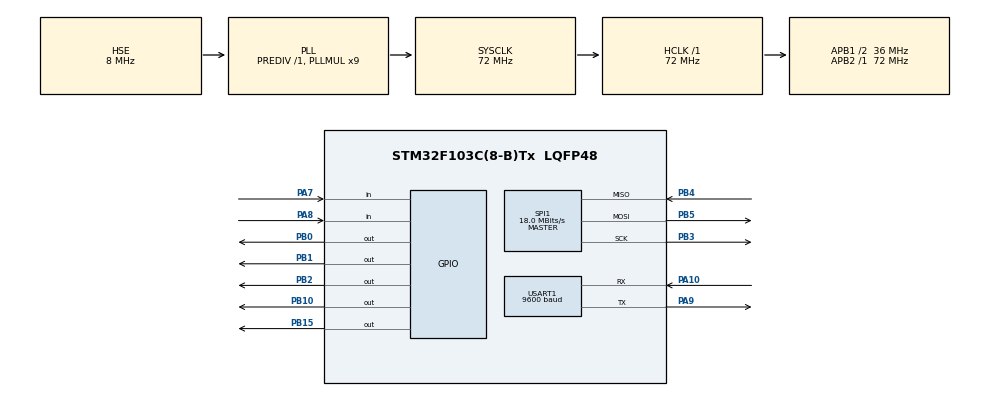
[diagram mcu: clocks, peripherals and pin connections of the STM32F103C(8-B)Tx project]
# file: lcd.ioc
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Mcu.Family=STM32F1
Mcu.Name=STM32F103C(8-B)Tx
Mcu.Package=LQFP48
NVIC.PriorityGroup=NVIC_PRIORITYGROUP_4
NVIC.USART1_IRQn=true\:0\:0\:false\:false\:true\:true\:true\:true
PA10.Mode=Asynchronous
PA10.Signal=USART1_RX
PA13.Mode=Serial_Wire
PA13.Signal=SYS_JTMS-SWDIO
PA14.Mode=Serial_Wire
PA14.Signal=SYS_JTCK-SWCLK
PA7.GPIO_PuPd=GPIO_PULLUP
PA7.Signal=GPIO_Input
PA8.GPIO_PuPd=GPIO_PULLUP
PA8.Signal=GPIO_Input
PA9.Mode=Asynchronous
PA9.Signal=USART1_TX
PB0.Signal=GPIO_Output
PB1.Signal=GPIO_Output
PB10.Signal=GPIO_Output
PB15.PinState=GPIO_PIN_RESET
PB15.Signal=GPIO_Output
PB2.Signal=GPIO_Output
PB3.Mode=Full_Duplex_Master
PB3.Signal=SPI1_SCK
PB4.Mode=Full_Duplex_Master
PB4.Signal=SPI1_MISO
PB5.Mode=Full_Duplex_Master
PB5.Signal=SPI1_MOSI
PD0-OSC_IN.Mode=HSE-External-Oscillator
PD0-OSC_IN.Signal=RCC_OSC_IN
PD1-OSC_OUT.Mode=HSE-External-Oscillator
PD1-OSC_OUT.Signal=RCC_OSC_OUT
ProjectManager.HeapSize=0x200
ProjectManager.StackSize=0x400
ProjectManager.TargetToolchain=MDK-ARM V5.27
RCC.AHBFreq_Value=72000000
RCC.APB1CLKDivider=RCC_HCLK_DIV2
RCC.APB1Freq_Value=36000000
RCC.APB1TimFreq_Value=72000000
RCC.APB2Freq_Value=72000000
RCC.APB2TimFreq_Value=72000000
RCC.HCLKFreq_Value=72000000
RCC.PLLMUL=RCC_PLL_MUL9
RCC.PLLSourceVirtual=RCC_PLLSOURCE_HSE
RCC.RTCClockSelection=RCC_RTCCLKSOURCE_HSE_DIV128
RCC.SYSCLKFreq_VALUE=72000000
RCC.SYSCLKSource=RCC_SYSCLKSOURCE_PLLCLK
RCC.USBFreq_Value=72000000
RTC.Date=15
RTC.Format=RTC_FORMAT_BIN
RTC.Hours=11
RTC.Minutes=47
RTC.WeekDay=RTC_WEEKDAY_SUNDAY
RTC.Year=23
SPI1.BaudRatePrescaler=SPI_BAUDRATEPRESCALER_4
SPI1.CLKPolarity=SPI_POLARITY_LOW
SPI1.CalculateBaudRate=18.0 MBits/s
SPI1.Direction=SPI_DIRECTION_2LINES
SPI1.Mode=SPI_MODE_MASTER
SPI1.VirtualType=VM_MASTER
TIM1.Channel-Output\ Compare1\ No\ Output=TIM_CHANNEL_1
USART1.BaudRate=9600
USART1.VirtualMode=VM_ASYNC
VP_RTC_VS_RTC_Activate.Mode=RTC_Enabled
VP_RTC_VS_RTC_Calendar.Mode=RTC_Calendar
VP_TIM1_VS_ClockSourceINT.Mode=Internal
VP_TIM1_VS_ClockSourceITR.Mode=TriggerSource_ITR1
VP_TIM1_VS_no_output1.Mode=Output Compare1 No Output
board=custom

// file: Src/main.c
/* USER CODE BEGIN Header */
/**
  ******************************************************************************
  * @file           : main.c
  * @brief          : Main program body
  ******************************************************************************
  * @attention
  *
  * <h2><center>&copy; Copyright (c) 2022 STMicroelectronics.
  * All rights reserved.</center></h2>
  *
  * This software component is licensed by ST under BSD 3-Clause license,
  * the "License"; You may not use this file except in compliance with the
  * License. You may obtain a copy of the License at:
  *                        opensource.org/licenses/BSD-3-Clause
  *
  ******************************************************************************
  */
/* USER CODE END Header */
#include "main.h"

/* USER CODE BEGIN Includes */
#include <stdio.h>
#include <string.h>
#include <stdlib.h>
#include <stdbool.h>

/* USER CODE END Includes */

/* USER CODE BEGIN PD */

#define CSX_PORT GPIOB
#define CSX_PIN GPIO_PIN_10

#define DC_PORT GPIOB
#define DC_PIN GPIO_PIN_0

#define RESET_PORT GPIOB
#define RESET_PIN GPIO_PIN_1

#define LCD_REST_LOW()   HAL_GPIO_WritePin(RESET_PORT, RESET_PIN, 0)
#define LCD_REST_HIGH()  HAL_GPIO_WritePin(RESET_PORT, RESET_PIN, 1)

#define LCD_DC_LOW()     HAL_GPIO_WritePin(DC_PORT, DC_PIN, 0)
#define LCD_DC_HIGH()    HAL_GPIO_WritePin(DC_PORT, DC_PIN, 1)

#define LCD_CS_LOW()     HAL_GPIO_WritePin(CSX_PORT, CSX_PIN, 0)
#define LCD_CS_HIGH()    HAL_GPIO_WritePin(CSX_PORT, CSX_PIN, 1)

const unsigned char ascii_3216[][64]={
{0x00,0x00,0x00,0x00,0x00,0x00,0x00,0x00,0x00,0x00,0x00,0x00,0x00,0x00,0x00,0x00,0x00,0x00,0x00,0x00,0x00,0x00,0x00,0x00,0x00,0x00,0x00,0x00,0x00,0x00,0x00,0x00,0x00,0x00,0x00,0x00,0x00,0x00,0x00,0x00,0x00,0x00,0x00,0x00,0x00,0x00,0x00,0x00,0x00,0x00,0x00,0x00,0x00,0x00,0x00,0x00,0x00,0x00,0x00,0x00,0x00,0x00,0x00,0x00},/*" ",0*/
{0x00,0x00,0x00,0x00,0x00,0x00,0x00,0x00,0x00,0x00,0xC0,0x01,0xC0,0x01,0xC0,0x01,0xC0,0x01,0xC0,0x01,0xC0,0x01,0xC0,0x01,0x80,0x00,0x80,0x00,0x80,0x00,0x80,0x00,0x80,0x00,0x80,0x00,0x80,0x00,0x00,0x00,0x00,0x00,0x00,0x00,0x00,0x00,0x80,0x01,0xC0,0x03,0xC0,0x03,0x80,0x01,0x00,0x00,0x00,0x00,0x00,0x00,0x00,0x00,0x00,0x00},/*"!",1*/
{0x00,0x00,0x00,0x00,0x00,0x00,0xE0,0x1C,0xE0,0x1C,0xF0,0x1E,0x70,0x0E,0x38,0x07,0x18,0x03,0x08,0x01,0x84,0x00,0x00,0x00,0x00,0x00,0x00,0x00,0x00,0x00,0x00,0x00,0x00,0x00,0x00,0x00,0x00,0x00,0x00,0x00,0x00,0x00,0x00,0x00,0x00,0x00,0x00,0x00,0x00,0x00,0x00,0x00,0x00,0x00,0x00,0x00,0x00,0x00,0x00,0x00,0x00,0x00,0x00,0x00},/*""",2*/
{0x00,0x00,0x00,0x00,0x00,0x00,0x00,0x00,0x00,0x00,0x00,0x00,0x20,0x10,0x20,0x10,0x20,0x10,0x20,0x10,0x20,0x10,0xFE,0x7F,0xFE,0x7F,0x10,0x08,0x10,0x08,0x10,0x08,0x10,0x08,0x10,0x08,0x10,0x08,0x10,0x08,0xFE,0x7F,0xFE,0x7F,0x08,0x04,0x08,0x04,0x08,0x04,0x08,0x04,0x08,0x04,0x00,0x00,0x00,0x00,0x00,0x00,0x00,0x00,0x00,0x00},/*"#",3*/
{0x00,0x00,0x00,0x00,0x00,0x00,0x00,0x00,0x00,0x01,0x00,0x01,0xC0,0x07,0x60,0x19,0x10,0x31,0x18,0x31,0x18,0x39,0x18,0x39,0x38,0x01,0x70,0x01,0xE0,0x01,0xC0,0x03,0x80,0x07,0x00,0x0F,0x00,0x1D,0x00,0x39,0x00,0x31,0x1C,0x31,0x1C,0x31,0x0C,0x31,0x0C,0x11,0x18,0x0D,0xE0,0x07,0x00,0x01,0x00,0x01,0x00,0x01,0x00,0x00,0x00,0x00},/*"$",4*/
{0x00,0x00,0x00,0x00,0x00,0x00,0x00,0x00,0x00,0x00,0x00,0x00,0x1C,0x10,0x36,0x18,0x63,0x08,0x63,0x0C,0x63,0x04,0x63,0x04,0x63,0x02,0x63,0x02,0x63,0x01,0x36,0x1D,0x9C,0x37,0x80,0x22,0x80,0x63,0x40,0x63,0x40,0x63,0x20,0x63,0x20,0x63,0x30,0x63,0x10,0x22,0x18,0x36,0x08,0x1C,0x00,0x00,0x00,0x00,0x00,0x00,0x00,0x00,0x00,0x00},/*"%",5*/
{0x00,0x00,0x00,0x00,0x00,0x00,0x00,0x00,0x00,0x00,0x00,0x00,0xF0,0x00,0x98,0x01,0x8C,0x01,0x8C,0x01,0x8C,0x01,0x8C,0x01,0x8C,0x00,0xCC,0x00,0x78,0x00,0x18,0x3E,0x1C,0x08,0x36,0x08,0x32,0x08,0x63,0x04,0x63,0x04,0xC3,0x04,0xC3,0x03,0x83,0x43,0x06,0x43,0x8E,0x26,0x78,0x1C,0x00,0x00,0x00,0x00,0x00,0x00,0x00,0x00,0x00,0x00},/*"&",6*/
{0x00,0x00,0x00,0x00,0x00,0x00,0x1C,0x00,0x3C,0x00,0x3C,0x00,0x30,0x00,0x30,0x00,0x10,0x00,0x0C,0x00,0x06,0x00,0x00,0x00,0x00,0x00,0x00,0x00,0x00,0x00,0x00,0x00,0x00,0x00,0x00,0x00,0x00,0x00,0x00,0x00,0x00,0x00,0x00,0x00,0x00,0x00,0x00,0x00,0x00,0x00,0x00,0x00,0x00,0x00,0x00,0x00,0x00,0x00,0x00,0x00,0x00,0x00,0x00,0x00},/*"'",7*/
{0x00,0x00,0x00,0x00,0x00,0x00,0x00,0x40,0x00,0x20,0x00,0x10,0x00,0x08,0x00,0x0C,0x00,0x04,0x00,0x06,0x00,0x03,0x00,0x03,0x00,0x03,0x80,0x01,0x80,0x01,0x80,0x01,0x80,0x01,0x80,0x01,0x80,0x01,0x80,0x01,0x80,0x01,0x00,0x03,0x00,0x03,0x00,0x03,0x00,0x06,0x00,0x06,0x00,0x0C,0x00,0x08,0x00,0x10,0x00,0x20,0x00,0x40,0x00,0x00},/*"(",8*/
{0x00,0x00,0x00,0x00,0x00,0x00,0x02,0x00,0x04,0x00,0x08,0x00,0x10,0x00,0x30,0x00,0x20,0x00,0x60,0x00,0xC0,0x00,0xC0,0x00,0xC0,0x00,0x80,0x01,0x80,0x01,0x80,0x01,0x80,0x01,0x80,0x01,0x80,0x01,0x80,0x01,0x80,0x01,0xC0,0x00,0xC0,0x00,0xC0,0x00,0x60,0x00,0x60,0x00,0x30,0x00,0x10,0x00,0x08,0x00,0x04,0x00,0x02,0x00,0x00,0x00},/*")",9*/
{0x00,0x00,0x00,0x00,0x00,0x00,0x00,0x00,0x00,0x00,0x00,0x00,0x00,0x00,0x00,0x00,0x00,0x01,0x80,0x03,0x80,0x03,0x00,0x01,0x1C,0x71,0x3C,0x79,0x78,0x3D,0xC0,0x07,0x00,0x01,0xC0,0x07,0x78,0x3D,0x3C,0x79,0x1C,0x71,0x00,0x01,0x80,0x03,0x80,0x03,0x80,0x01,0x00,0x00,0x00,0x00,0x00,0x00,0x00,0x00,0x00,0x00,0x00,0x00,0x00,0x00},/*"*",10*/
{0x00,0x00,0x00,0x00,0x00,0x00,0x00,0x00,0x00,0x00,0x00,0x00,0x00,0x00,0x00,0x00,0x00,0x00,0x00,0x01,0x00,0x01,0x00,0x01,0x00,0x01,0x00,0x01,0x00,0x01,0x00,0x01,0xFC,0x7F,0x00,0x01,0x00,0x01,0x00,0x01,0x00,0x01,0x00,0x01,0x00,0x01,0x00,0x01,0x00,0x00,0x00,0x00,0x00,0x00,0x00,0x00,0x00,0x00,0x00,0x00,0x00,0x00,0x00,0x00},/*"+",11*/
{0x00,0x00,0x00,0x00,0x00,0x00,0x00,0x00,0x00,0x00,0x00,0x00,0x00,0x00,0x00,0x00,0x00,0x00,0x00,0x00,0x00,0x00,0x00,0x00,0x00,0x00,0x00,0x00,0x00,0x00,0x00,0x00,0x00,0x00,0x00,0x00,0x00,0x00,0x00,0x00,0x00,0x00,0x00,0x00,0x00,0x00,0x00,0x00,0x1C,0x00,0x3C,0x00,0x3C,0x00,0x30,0x00,0x30,0x00,0x10,0x00,0x0C,0x00,0x06,0x00},/*",",12*/
{0x00,0x00,0x00,0x00,0x00,0x00,0x00,0x00,0x00,0x00,0x00,0x00,0x00,0x00,0x00,0x00,0x00,0x00,0x00,0x00,0x00,0x00,0x00,0x00,0x00,0x00,0x00,0x00,0x00,0x00,0x00,0x00,0xFE,0x7F,0x00,0x00,0x00,0x00,0x00,0x00,0x00,0x00,0x00,0x00,0x00,0x00,0x00,0x00,0x00,0x00,0x00,0x00,0x00,0x00,0x00,0x00,0x00,0x00,0x00,0x00,0x00,0x00,0x00,0x00},/*"-",13*/
{0x00,0x00,0x00,0x00,0x00,0x00,0x00,0x00,0x00,0x00,0x00,0x00,0x00,0x00,0x00,0x00,0x00,0x00,0x00,0x00,0x00,0x00,0x00,0x00,0x00,0x00,0x00,0x00,0x00,0x00,0x00,0x00,0x00,0x00,0x00,0x00,0x00,0x00,0x00,0x00,0x00,0x00,0x00,0x00,0x00,0x00,0x18,0x00,0x3C,0x00,0x3C,0x00,0x18,0x00,0x00,0x00,0x00,0x00,0x00,0x00,0x00,0x00,0x00,0x00},/*".",14*/
{0x00,0x00,0x00,0x00,0x00,0x00,0x00,0x40,0x00,0x60,0x00,0x20,0x00,0x30,0x00,0x10,0x00,0x18,0x00,0x08,0x00,0x0C,0x00,0x04,0x00,0x06,0x00,0x02,0x00,0x03,0x00,0x01,0x80,0x01,0x80,0x00,0xC0,0x00,0x40,0x00,0x60,0x00,0x20,0x00,0x30,0x00,0x10,0x00,0x18,0x00,0x08,0x00,0x0C,0x00,0x04,0x00,0x06,0x00,0x02,0x00,0x00,0x00,0x00,0x00},/*"/",15*/
{0x00,0x00,0x00,0x00,0x00,0x00,0x00,0x00,0x00,0x00,0x00,0x00,0xC0,0x07,0x60,0x0C,0x30,0x18,0x18,0x30,0x18,0x30,0x18,0x20,0x0C,0x60,0x0C,0x60,0x0C,0x60,0x0C,0x60,0x0C,0x60,0x0C,0x60,0x0C,0x60,0x0C,0x60,0x0C,0x60,0x18,0x20,0x18,0x30,0x18,0x30,0x30,0x18,0x60,0x0C,0xC0,0x07,0x00,0x00,0x00,0x00,0x00,0x00,0x00,0x00,0x00,0x00},/*"0",16*/
{0x00,0x00,0x00,0x00,0x00,0x00,0x00,0x00,0x00,0x00,0x00,0x00,0x00,0x01,0x80,0x01,0xF8,0x01,0x80,0x01,0x80,0x01,0x80,0x01,0x80,0x01,0x80,0x01,0x80,0x01,0x80,0x01,0x80,0x01,0x80,0x01,0x80,0x01,0x80,0x01,0x80,0x01,0x80,0x01,0x80,0x01,0x80,0x01,0x80,0x01,0xC0,0x03,0xF8,0x1F,0x00,0x00,0x00,0x00,0x00,0x00,0x00,0x00,0x00,0x00},/*"1",17*/
{0x00,0x00,0x00,0x00,0x00,0x00,0x00,0x00,0x00,0x00,0x00,0x00,0xE0,0x07,0x10,0x1C,0x08,0x18,0x04,0x30,0x04,0x30,0x0C,0x30,0x0C,0x30,0x00,0x30,0x00,0x18,0x00,0x08,0x00,0x04,0x00,0x02,0x00,0x01,0x80,0x00,0x40,0x00,0x20,0x20,0x10,0x20,0x08,0x20,0x04,0x30,0xFC,0x1F,0xFC,0x1F,0x00,0x00,0x00,0x00,0x00,0x00,0x00,0x00,0x00,0x00},/*"2",18*/
{0x00,0x00,0x00,0x00,0x00,0x00,0x00,0x00,0x00,0x00,0x00,0x00,0xE0,0x03,0x18,0x0E,0x0C,0x0C,0x0C,0x18,0x0C,0x18,0x0C,0x18,0x00,0x18,0x00,0x0C,0x00,0x06,0xC0,0x03,0x00,0x0E,0x00,0x18,0x00,0x10,0x00,0x30,0x00,0x30,0x0C,0x30,0x0C,0x30,0x0C,0x10,0x0C,0x18,0x18,0x0C,0xE0,0x03,0x00,0x00,0x00,0x00,0x00,0x00,0x00,0x00,0x00,0x00},/*"3",19*/
{0x00,0x00,0x00,0x00,0x00,0x00,0x00,0x00,0x00,0x00,0x00,0x00,0x00,0x0C,0x00,0x0E,0x00,0x0E,0x00,0x0F,0x80,0x0E,0x80,0x0E,0x40,0x0E,0x60,0x0E,0x20,0x0E,0x10,0x0E,0x10,0x0E,0x08,0x0E,0x04,0x0E,0x04,0x0E,0xFE,0x7F,0x00,0x0E,0x00,0x0E,0x00,0x0E,0x00,0x0E,0x00,0x0E,0x00,0x0E,0xC0,0x7F,0x00,0x00,0x00,0x00,0x00,0x00,0x00,0x00},/*"4",20*/
{0x00,0x00,0x00,0x00,0x00,0x00,0x00,0x00,0x00,0x00,0x00,0x00,0xF0,0x3F,0xF0,0x3F,0x10,0x00,0x10,0x00,0x10,0x00,0x08,0x00,0x08,0x00,0xC8,0x07,0x28,0x0C,0x18,0x18,0x08,0x10,0x00,0x30,0x00,0x30,0x00,0x30,0x00,0x30,0x0C,0x30,0x0C,0x30,0x04,0x18,0x04,0x18,0x08,0x0C,0xF0,0x03,0x00,0x00,0x00,0x00,0x00,0x00,0x00,0x00,0x00,0x00},/*"5",21*/
{0x00,0x00,0x00,0x00,0x00,0x00,0x00,0x00,0x00,0x00,0x00,0x00,0x80,0x0F,0xC0,0x10,0x20,0x30,0x10,0x30,0x18,0x00,0x18,0x00,0x08,0x00,0x0C,0x00,0x8C,0x0F,0x6C,0x18,0x3C,0x30,0x1C,0x60,0x0C,0x60,0x0C,0x60,0x0C,0x60,0x0C,0x60,0x18,0x60,0x18,0x20,0x30,0x30,0x60,0x18,0xC0,0x07,0x00,0x00,0x00,0x00,0x00,0x00,0x00,0x00,0x00,0x00},/*"6",22*/
{0x00,0x00,0x00,0x00,0x00,0x00,0x00,0x00,0x00,0x00,0x00,0x00,0xF8,0x3F,0xF8,0x3F,0x1C,0x10,0x0C,0x08,0x04,0x08,0x04,0x04,0x00,0x04,0x00,0x02,0x00,0x02,0x00,0x01,0x00,0x01,0x00,0x01,0x80,0x00,0x80,0x00,0x80,0x00,0xC0,0x00,0xC0,0x00,0xC0,0x00,0xC0,0x00,0xC0,0x00,0xC0,0x00,0x00,0x00,0x00,0x00,0x00,0x00,0x00,0x00,0x00,0x00},/*"7",23*/
{0x00,0x00,0x00,0x00,0x00,0x00,0x00,0x00,0x00,0x00,0x00,0x00,0xE0,0x07,0x30,0x0C,0x18,0x18,0x0C,0x30,0x0C,0x30,0x0C,0x30,0x1C,0x30,0x38,0x18,0x70,0x08,0xE0,0x07,0xB0,0x07,0x18,0x0E,0x0C,0x1C,0x06,0x38,0x06,0x30,0x06,0x30,0x06,0x30,0x06,0x30,0x0C,0x18,0x18,0x0C,0xE0,0x03,0x00,0x00,0x00,0x00,0x00,0x00,0x00,0x00,0x00,0x00},/*"8",24*/
{0x00,0x00,0x00,0x00,0x00,0x00,0x00,0x00,0x00,0x00,0x00,0x00,0xE0,0x03,0x18,0x04,0x0C,0x08,0x0C,0x18,0x06,0x10,0x06,0x30,0x06,0x30,0x06,0x30,0x06,0x30,0x06,0x38,0x0C,0x3C,0x18,0x36,0xF0,0x31,0x00,0x30,0x00,0x18,0x00,0x18,0x00,0x18,0x0C,0x0C,0x0C,0x06,0x0C,0x03,0xF0,0x01,0x00,0x00,0x00,0x00,0x00,0x00,0x00,0x00,0x00,0x00},/*"9",25*/
{0x00,0x00,0x00,0x00,0x00,0x00,0x00,0x00,0x00,0x00,0x00,0x00,0x00,0x00,0x00,0x00,0x00,0x00,0x00,0x00,0x00,0x00,0x00,0x00,0x00,0x00,0x80,0x01,0xC0,0x03,0xC0,0x03,0x80,0x01,0x00,0x00,0x00,0x00,0x00,0x00,0x00,0x00,0x00,0x00,0x00,0x00,0x80,0x01,0xC0,0x03,0xC0,0x03,0x80,0x01,0x00,0x00,0x00,0x00,0x00,0x00,0x00,0x00,0x00,0x00},/*":",26*/
{0x00,0x00,0x00,0x00,0x00,0x00,0x00,0x00,0x00,0x00,0x00,0x00,0x00,0x00,0x00,0x00,0x00,0x00,0x00,0x00,0x00,0x00,0x00,0x00,0x00,0x00,0xC0,0x00,0xC0,0x00,0x00,0x00,0x00,0x00,0x00,0x00,0x00,0x00,0x00,0x00,0x00,0x00,0x00,0x00,0x00,0x00,0x00,0x00,0x00,0x00,0xC0,0x00,0xC0,0x00,0x80,0x00,0x80,0x00,0x40,0x00,0x40,0x00,0x00,0x00},/*";",27*/
{0x00,0x00,0x00,0x00,0x00,0x00,0x00,0x00,0x00,0x00,0x00,0x20,0x00,0x10,0x00,0x08,0x00,0x04,0x00,0x06,0x00,0x03,0x80,0x01,0xC0,0x00,0x60,0x00,0x30,0x00,0x18,0x00,0x0C,0x00,0x18,0x00,0x30,0x00,0x60,0x00,0xC0,0x00,0x80,0x01,0x00,0x03,0x00,0x06,0x00,0x04,0x00,0x08,0x00,0x10,0x00,0x20,0x00,0x00,0x00,0x00,0x00,0x00,0x00,0x00},/*"<",28*/
{0x00,0x00,0x00,0x00,0x00,0x00,0x00,0x00,0x00,0x00,0x00,0x00,0x00,0x00,0x00,0x00,0x00,0x00,0x00,0x00,0x00,0x00,0x00,0x00,0x00,0x00,0xFE,0x7F,0x00,0x00,0x00,0x00,0x00,0x00,0x00,0x00,0x00,0x00,0xFE,0x7F,0x00,0x00,0x00,0x00,0x00,0x00,0x00,0x00,0x00,0x00,0x00,0x00,0x00,0x00,0x00,0x00,0x00,0x00,0x00,0x00,0x00,0x00,0x00,0x00},/*"=",29*/
{0x00,0x00,0x00,0x00,0x00,0x00,0x00,0x00,0x00,0x00,0x04,0x00,0x08,0x00,0x10,0x00,0x20,0x00,0x60,0x00,0xC0,0x00,0x80,0x01,0x00,0x03,0x00,0x06,0x00,0x0C,0x00,0x18,0x00,0x30,0x00,0x18,0x00,0x0C,0x00,0x06,0x00,0x03,0x80,0x01,0xC0,0x00,0x60,0x00,0x20,0x00,0x10,0x00,0x08,0x00,0x04,0x00,0x00,0x00,0x00,0x00,0x00,0x00,0x00,0x00},/*">",30*/
{0x00,0x00,0x00,0x00,0x00,0x00,0x00,0x00,0x00,0x00,0xC0,0x07,0x30,0x18,0x08,0x30,0x08,0x60,0x0C,0x60,0x1C,0x60,0x1C,0x60,0x1C,0x60,0x00,0x30,0x00,0x1C,0x00,0x06,0x00,0x01,0x80,0x00,0x80,0x00,0x80,0x00,0x80,0x00,0x00,0x00,0x00,0x00,0x80,0x01,0xC0,0x03,0xC0,0x03,0x80,0x01,0x00,0x00,0x00,0x00,0x00,0x00,0x00,0x00,0x00,0x00},/*"?",31*/
{0x00,0x00,0x00,0x00,0x00,0x00,0x00,0x00,0x00,0x00,0x00,0x00,0xC0,0x07,0x60,0x18,0x10,0x30,0x18,0x20,0x0C,0x2F,0x8C,0x4D,0x86,0x4C,0xC6,0x4C,0xC6,0x4C,0x66,0x4C,0x66,0x44,0x66,0x44,0x66,0x26,0x66,0x26,0x66,0x15,0xCC,0x1C,0x0C,0x40,0x08,0x20,0x18,0x30,0x30,0x18,0xC0,0x07,0x00,0x00,0x00,0x00,0x00,0x00,0x00,0x00,0x00,0x00},/*"@",32*/
{0x00,0x00,0x00,0x00,0x00,0x00,0x00,0x00,0x00,0x00,0x00,0x01,0xC0,0x01,0xC0,0x01,0xC0,0x01,0x40,0x01,0x60,0x03,0x20,0x03,0x20,0x03,0x20,0x03,0x30,0x06,0x10,0x06,0x10,0x06,0x10,0x06,0xF8,0x0F,0x08,0x0C,0x08,0x0C,0x08,0x0C,0x0C,0x0C,0x04,0x18,0x04,0x18,0x06,0x18,0x1F,0x7C,0x00,0x00,0x00,0x00,0x00,0x00,0x00,0x00,0x00,0x00},/*"A",33*/
{0x00,0x00,0x00,0x00,0x00,0x00,0x00,0x00,0x00,0x00,0x00,0x00,0xFE,0x07,0x18,0x1C,0x18,0x38,0x18,0x30,0x18,0x30,0x18,0x30,0x18,0x30,0x18,0x18,0x18,0x0C,0xF8,0x07,0x18,0x18,0x18,0x30,0x18,0x20,0x18,0x60,0x18,0x60,0x18,0x60,0x18,0x60,0x18,0x60,0x18,0x30,0x18,0x18,0xFE,0x0F,0x00,0x00,0x00,0x00,0x00,0x00,0x00,0x00,0x00,0x00},/*"B",34*/
{0x00,0x00,0x00,0x00,0x00,0x00,0x00,0x00,0x00,0x00,0x00,0x00,0xC0,0x27,0x60,0x38,0x10,0x30,0x18,0x20,0x0C,0x40,0x0C,0x40,0x04,0x00,0x06,0x00,0x06,0x00,0x06,0x00,0x06,0x00,0x06,0x00,0x06,0x00,0x06,0x00,0x06,0x00,0x0C,0x40,0x0C,0x40,0x0C,0x20,0x18,0x30,0x30,0x18,0xC0,0x07,0x00,0x00,0x00,0x00,0x00,0x00,0x00,0x00,0x00,0x00},/*"C",35*/
{0x00,0x00,0x00,0x00,0x00,0x00,0x00,0x00,0x00,0x00,0x00,0x00,0xFE,0x03,0x18,0x0E,0x18,0x18,0x18,0x30,0x18,0x30,0x18,0x30,0x18,0x60,0x18,0x60,0x18,0x60,0x18,0x60,0x18,0x60,0x18,0x60,0x18,0x60,0x18,0x60,0x18,0x60,0x18,0x30,0x18,0x30,0x18,0x10,0x18,0x18,0x18,0x0E,0xFE,0x03,0x00,0x00,0x00,0x00,0x00,0x00,0x00,0x00,0x00,0x00},/*"D",36*/
{0x00,0x00,0x00,0x00,0x00,0x00,0x00,0x00,0x00,0x00,0x00,0x00,0xFE,0x3F,0x18,0x30,0x18,0x20,0x18,0x60,0x18,0x40,0x18,0x00,0x18,0x08,0x18,0x08,0x18,0x0C,0xF8,0x0F,0x18,0x0C,0x18,0x08,0x18,0x08,0x18,0x00,0x18,0x00,0x18,0x00,0x18,0x40,0x18,0x40,0x18,0x20,0x18,0x30,0xFE,0x3F,0x00,0x00,0x00,0x00,0x00,0x00,0x00,0x00,0x00,0x00},/*"E",37*/
{0x00,0x00,0x00,0x00,0x00,0x00,0x00,0x00,0x00,0x00,0x00,0x00,0xFE,0x7F,0x18,0x70,0x18,0x40,0x18,0xC0,0x18,0x80,0x18,0x00,0x18,0x10,0x18,0x10,0x18,0x18,0xF8,0x1F,0x18,0x18,0x18,0x10,0x18,0x10,0x18,0x00,0x18,0x00,0x18,0x00,0x18,0x00,0x18,0x00,0x18,0x00,0x18,0x00,0x7E,0x00,0x00,0x00,0x00,0x00,0x00,0x00,0x00,0x00,0x00,0x00},/*"F",38*/
{0x00,0x00,0x00,0x00,0x00,0x00,0x00,0x00,0x00,0x00,0x00,0x00,0xC0,0x13,0x70,0x1C,0x10,0x10,0x18,0x10,0x0C,0x20,0x0C,0x20,0x04,0x00,0x06,0x00,0x06,0x00,0x06,0x00,0x06,0x00,0x06,0x00,0x06,0xFC,0x06,0x30,0x06,0x30,0x0C,0x30,0x0C,0x30,0x18,0x30,0x18,0x30,0x30,0x08,0xC0,0x07,0x00,0x00,0x00,0x00,0x00,0x00,0x00,0x00,0x00,0x00},/*"G",39*/
{0x00,0x00,0x00,0x00,0x00,0x00,0x00,0x00,0x00,0x00,0x00,0x00,0x3F,0x7E,0x0C,0x18,0x0C,0x18,0x0C,0x18,0x0C,0x18,0x0C,0x18,0x0C,0x18,0x0C,0x18,0x0C,0x18,0x0C,0x18,0xFC,0x1F,0x0C,0x18,0x0C,0x18,0x0C,0x18,0x0C,0x18,0x0C,0x18,0x0C,0x18,0x0C,0x18,0x0C,0x18,0x0C,0x18,0x3F,0x7E,0x00,0x00,0x00,0x00,0x00,0x00,0x00,0x00,0x00,0x00},/*"H",40*/
{0x00,0x00,0x00,0x00,0x00,0x00,0x00,0x00,0x00,0x00,0x00,0x00,0xF8,0x1F,0x80,0x01,0x80,0x01,0x80,0x01,0x80,0x01,0x80,0x01,0x80,0x01,0x80,0x01,0x80,0x01,0x80,0x01,0x80,0x01,0x80,0x01,0x80,0x01,0x80,0x01,0x80,0x01,0x80,0x01,0x80,0x01,0x80,0x01,0x80,0x01,0x80,0x01,0xF8,0x1F,0x00,0x00,0x00,0x00,0x00,0x00,0x00,0x00,0x00,0x00},/*"I",41*/
{0x00,0x00,0x00,0x00,0x00,0x00,0x00,0x00,0x00,0x00,0x00,0x00,0xE0,0x7F,0x00,0x06,0x00,0x06,0x00,0x06,0x00,0x06,0x00,0x06,0x00,0x06,0x00,0x06,0x00,0x06,0x00,0x06,0x00,0x06,0x00,0x06,0x00,0x06,0x00,0x06,0x00,0x06,0x00,0x06,0x00,0x06,0x00,0x06,0x00,0x06,0x00,0x06,0x00,0x06,0x00,0x06,0x0E,0x06,0x0E,0x03,0x8E,0x01,0xFC,0x00},/*"J",42*/
{0x00,0x00,0x00,0x00,0x00,0x00,0x00,0x00,0x00,0x00,0x00,0x00,0x7E,0x7C,0x18,0x18,0x18,0x08,0x18,0x04,0x18,0x06,0x18,0x02,0x18,0x01,0x98,0x01,0x98,0x01,0xD8,0x01,0xB8,0x03,0x38,0x03,0x18,0x07,0x18,0x06,0x18,0x0E,0x18,0x0C,0x18,0x1C,0x18,0x18,0x18,0x30,0x18,0x30,0x7E,0xFC,0x00,0x00,0x00,0x00,0x00,0x00,0x00,0x00,0x00,0x00},/*"K",43*/
{0x00,0x00,0x00,0x00,0x00,0x00,0x00,0x00,0x00,0x00,0x00,0x00,0x7E,0x00,0x18,0x00,0x18,0x00,0x18,0x00,0x18,0x00,0x18,0x00,0x18,0x00,0x18,0x00,0x18,0x00,0x18,0x00,0x18,0x00,0x18,0x00,0x18,0x00,0x18,0x00,0x18,0x00,0x18,0x00,0x18,0x40,0x18,0x40,0x18,0x20,0x18,0x30,0xFE,0x3F,0x00,0x00,0x00,0x00,0x00,0x00,0x00,0x00,0x00,0x00},/*"L",44*/
{0x00,0x00,0x00,0x00,0x00,0x00,0x00,0x00,0x00,0x00,0x00,0x00,0x1F,0xF8,0x1C,0x38,0x1C,0x38,0x1C,0x38,0x1C,0x3C,0x34,0x34,0x34,0x34,0x34,0x34,0x34,0x36,0x74,0x32,0x64,0x32,0x64,0x32,0x64,0x32,0x64,0x31,0xC4,0x31,0xC4,0x31,0xC4,0x31,0xC4,0x30,0xC4,0x30,0x84,0x30,0x9F,0xFC,0x00,0x00,0x00,0x00,0x00,0x00,0x00,0x00,0x00,0x00},/*"M",45*/
{0x00,0x00,0x00,0x00,0x00,0x00,0x00,0x00,0x00,0x00,0x00,0x00,0x1F,0x7C,0x1C,0x10,0x3C,0x10,0x34,0x10,0x34,0x10,0x74,0x10,0x64,0x10,0xE4,0x10,0xC4,0x10,0xC4,0x11,0x84,0x11,0x84,0x13,0x04,0x13,0x04,0x17,0x04,0x16,0x04,0x1E,0x04,0x1C,0x04,0x1C,0x04,0x1C,0x04,0x18,0x1F,0x18,0x00,0x00,0x00,0x00,0x00,0x00,0x00,0x00,0x00,0x00},/*"N",46*/
{0x00,0x00,0x00,0x00,0x00,0x00,0x00,0x00,0x00,0x00,0x00,0x00,0xC0,0x03,0x30,0x0C,0x18,0x18,0x08,0x10,0x0C,0x30,0x0C,0x30,0x06,0x60,0x06,0x60,0x06,0x60,0x06,0x60,0x06,0x60,0x06,0x60,0x06,0x60,0x06,0x60,0x06,0x60,0x0C,0x20,0x0C,0x30,0x08,0x10,0x18,0x18,0x30,0x0C,0xC0,0x03,0x00,0x00,0x00,0x00,0x00,0x00,0x00,0x00,0x00,0x00},/*"O",47*/
{0x00,0x00,0x00,0x00,0x00,0x00,0x00,0x00,0x00,0x00,0x00,0x00,0xFE,0x0F,0x18,0x18,0x18,0x30,0x18,0x60,0x18,0x60,0x18,0x60,0x18,0x60,0x18,0x60,0x18,0x30,0x18,0x18,0xF8,0x0F,0x18,0x00,0x18,0x00,0x18,0x00,0x18,0x00,0x18,0x00,0x18,0x00,0x18,0x00,0x18,0x00,0x18,0x00,0x7E,0x00,0x00,0x00,0x00,0x00,0x00,0x00,0x00,0x00,0x00,0x00},/*"P",48*/
{0x00,0x00,0x00,0x00,0x00,0x00,0x00,0x00,0x00,0x00,0x00,0x00,0xC0,0x03,0x30,0x0C,0x18,0x18,0x0C,0x10,0x0C,0x30,0x0C,0x20,0x06,0x60,0x06,0x60,0x06,0x60,0x06,0x60,0x06,0x60,0x06,0x60,0x06,0x60,0x06,0x60,0x06,0x60,0xE4,0x61,0x2C,0x33,0x1C,0x32,0x18,0x16,0x30,0x0E,0xC0,0x07,0x00,0x4C,0x00,0x7C,0x00,0x38,0x00,0x00,0x00,0x00},/*"Q",49*/
{0x00,0x00,0x00,0x00,0x00,0x00,0x00,0x00,0x00,0x00,0x00,0x00,0xFE,0x07,0x18,0x1C,0x18,0x38,0x18,0x30,0x18,0x30,0x18,0x30,0x18,0x30,0x18,0x18,0x18,0x0C,0xF8,0x07,0x98,0x03,0x18,0x03,0x18,0x07,0x18,0x06,0x18,0x06,0x18,0x0E,0x18,0x0C,0x18,0x0C,0x18,0x1C,0x18,0x18,0x7E,0x78,0x00,0x00,0x00,0x00,0x00,0x00,0x00,0x00,0x00,0x00},/*"R",50*/
{0x00,0x00,0x00,0x00,0x00,0x00,0x00,0x00,0x00,0x00,0x00,0x00,0xE0,0x27,0x30,0x38,0x18,0x30,0x0C,0x20,0x0C,0x20,0x0C,0x00,0x0C,0x00,0x18,0x00,0x78,0x00,0xE0,0x03,0x80,0x0F,0x00,0x1E,0x00,0x38,0x00,0x70,0x00,0x60,0x04,0x60,0x04,0x60,0x08,0x60,0x18,0x30,0x38,0x18,0xC8,0x0F,0x00,0x00,0x00,0x00,0x00,0x00,0x00,0x00,0x00,0x00},/*"S",51*/
{0x00,0x00,0x00,0x00,0x00,0x00,0x00,0x00,0x00,0x00,0x00,0x00,0xFC,0x3F,0x8C,0x21,0x84,0x61,0x82,0x41,0x82,0x41,0x80,0x01,0x80,0x01,0x80,0x01,0x80,0x01,0x80,0x01,0x80,0x01,0x80,0x01,0x80,0x01,0x80,0x01,0x80,0x01,0x80,0x01,0x80,0x01,0x80,0x01,0x80,0x01,0x80,0x01,0xE0,0x07,0x00,0x00,0x00,0x00,0x00,0x00,0x00,0x00,0x00,0x00},/*"T",52*/
{0x00,0x00,0x00,0x00,0x00,0x00,0x00,0x00,0x00,0x00,0x00,0x00,0x3F,0x7C,0x0C,0x10,0x0C,0x10,0x0C,0x10,0x0C,0x10,0x0C,0x10,0x0C,0x10,0x0C,0x10,0x0C,0x10,0x0C,0x10,0x0C,0x10,0x0C,0x10,0x0C,0x10,0x0C,0x10,0x0C,0x10,0x0C,0x10,0x0C,0x10,0x0C,0x10,0x08,0x08,0x38,0x04,0xE0,0x03,0x00,0x00,0x00,0x00,0x00,0x00,0x00,0x00,0x00,0x00},/*"U",53*/
{0x00,0x00,0x00,0x00,0x00,0x00,0x00,0x00,0x00,0x00,0x00,0x00,0x3E,0xF8,0x18,0x20,0x18,0x20,0x18,0x20,0x30,0x10,0x30,0x10,0x30,0x10,0x30,0x10,0x60,0x08,0x60,0x08,0x60,0x08,0xE0,0x0C,0xC0,0x04,0xC0,0x04,0xC0,0x04,0x80,0x03,0x80,0x03,0x80,0x03,0x80,0x03,0x00,0x01,0x00,0x01,0x00,0x00,0x00,0x00,0x00,0x00,0x00,0x00,0x00,0x00},/*"V",54*/
{0x00,0x00,0x00,0x00,0x00,0x00,0x00,0x00,0x00,0x00,0x00,0x00,0xDF,0xF3,0x86,0x61,0x86,0x21,0x86,0x21,0x8C,0x21,0x0C,0x21,0x8C,0x23,0x8C,0x13,0x8C,0x13,0x8C,0x13,0x4C,0x13,0x58,0x12,0x58,0x16,0x58,0x0E,0x38,0x0E,0x38,0x0E,0x38,0x0E,0x30,0x0C,0x10,0x04,0x10,0x04,0x10,0x04,0x00,0x00,0x00,0x00,0x00,0x00,0x00,0x00,0x00,0x00},/*"W",55*/
{0x00,0x00,0x00,0x00,0x00,0x00,0x00,0x00,0x00,0x00,0x00,0x00,0x7E,0x3E,0x18,0x08,0x38,0x08,0x30,0x04,0x30,0x04,0x70,0x02,0x60,0x02,0xE0,0x01,0xC0,0x01,0xC0,0x01,0x80,0x01,0x80,0x03,0x40,0x03,0x40,0x07,0x20,0x06,0x20,0x06,0x10,0x0C,0x10,0x0C,0x08,0x18,0x08,0x18,0x3E,0x7C,0x00,0x00,0x00,0x00,0x00,0x00,0x00,0x00,0x00,0x00},/*"X",56*/
{0x00,0x00,0x00,0x00,0x00,0x00,0x00,0x00,0x00,0x00,0x00,0x00,0x7E,0x7C,0x1C,0x10,0x18,0x10,0x18,0x08,0x30,0x08,0x30,0x0C,0x70,0x04,0x60,0x04,0x60,0x02,0xC0,0x02,0xC0,0x02,0xC0,0x01,0x80,0x01,0x80,0x01,0x80,0x01,0x80,0x01,0x80,0x01,0x80,0x01,0x80,0x01,0x80,0x01,0xE0,0x07,0x00,0x00,0x00,0x00,0x00,0x00,0x00,0x00,0x00,0x00},/*"Y",57*/
{0x00,0x00,0x00,0x00,0x00,0x00,0x00,0x00,0x00,0x00,0x00,0x00,0xF8,0x3F,0x18,0x18,0x08,0x18,0x04,0x0C,0x04,0x0E,0x00,0x06,0x00,0x07,0x00,0x03,0x80,0x03,0x80,0x01,0xC0,0x01,0xC0,0x00,0xE0,0x00,0x60,0x00,0x70,0x00,0x30,0x00,0x38,0x20,0x18,0x20,0x1C,0x10,0x0C,0x18,0xFE,0x1F,0x00,0x00,0x00,0x00,0x00,0x00,0x00,0x00,0x00,0x00},/*"Z",58*/
{0x00,0x00,0x00,0x00,0x00,0x00,0xC0,0x3F,0x40,0x00,0x40,0x00,0x40,0x00,0x40,0x00,0x40,0x00,0x40,0x00,0x40,0x00,0x40,0x00,0x40,0x00,0x40,0x00,0x40,0x00,0x40,0x00,0x40,0x00,0x40,0x00,0x40,0x00,0x40,0x00,0x40,0x00,0x40,0x00,0x40,0x00,0x40,0x00,0x40,0x00,0x40,0x00,0x40,0x00,0x40,0x00,0x40,0x00,0xC0,0x3F,0x00,0x00,0x00,0x00},/*"[",59*/
{0x00,0x00,0x00,0x00,0x00,0x00,0x00,0x00,0x00,0x00,0x08,0x00,0x18,0x00,0x18,0x00,0x10,0x00,0x30,0x00,0x20,0x00,0x60,0x00,0x60,0x00,0x40,0x00,0xC0,0x00,0x80,0x00,0x80,0x01,0x80,0x01,0x00,0x01,0x00,0x03,0x00,0x02,0x00,0x06,0x00,0x06,0x00,0x04,0x00,0x0C,0x00,0x08,0x00,0x18,0x00,0x18,0x00,0x10,0x00,0x30,0x00,0x20,0x00,0x00},/*"\",60*/
{0x00,0x00,0x00,0x00,0x00,0x00,0xFC,0x03,0x00,0x02,0x00,0x02,0x00,0x02,0x00,0x02,0x00,0x02,0x00,0x02,0x00,0x02,0x00,0x02,0x00,0x02,0x00,0x02,0x00,0x02,0x00,0x02,0x00,0x02,0x00,0x02,0x00,0x02,0x00,0x02,0x00,0x02,0x00,0x02,0x00,0x02,0x00,0x02,0x00,0x02,0x00,0x02,0x00,0x02,0x00,0x02,0x00,0x02,0xFC,0x03,0x00,0x00,0x00,0x00},/*"]",61*/
{0x00,0x00,0x00,0x00,0x00,0x00,0x80,0x07,0xC0,0x06,0x20,0x08,0x10,0x10,0x00,0x00,0x00,0x00,0x00,0x00,0x00,0x00,0x00,0x00,0x00,0x00,0x00,0x00,0x00,0x00,0x00,0x00,0x00,0x00,0x00,0x00,0x00,0x00,0x00,0x00,0x00,0x00,0x00,0x00,0x00,0x00,0x00,0x00,0x00,0x00,0x00,0x00,0x00,0x00,0x00,0x00,0x00,0x00,0x00,0x00,0x00,0x00,0x00,0x00},/*"^",62*/
{0x00,0x00,0x00,0x00,0x00,0x00,0x00,0x00,0x00,0x00,0x00,0x00,0x00,0x00,0x00,0x00,0x00,0x00,0x00,0x00,0x00,0x00,0x00,0x00,0x00,0x00,0x00,0x00,0x00,0x00,0x00,0x00,0x00,0x00,0x00,0x00,0x00,0x00,0x00,0x00,0x00,0x00,0x00,0x00,0x00,0x00,0x00,0x00,0x00,0x00,0x00,0x00,0x00,0x00,0x00,0x00,0x00,0x00,0x00,0x00,0x00,0x00,0xFF,0xFF},/*"_",63*/
{0x00,0x00,0x00,0x00,0x00,0x00,0x78,0x00,0xC0,0x00,0x00,0x01,0x00,0x00,0x00,0x00,0x00,0x00,0x00,0x00,0x00,0x00,0x00,0x00,0x00,0x00,0x00,0x00,0x00,0x00,0x00,0x00,0x00,0x00,0x00,0x00,0x00,0x00,0x00,0x00,0x00,0x00,0x00,0x00,0x00,0x00,0x00,0x00,0x00,0x00,0x00,0x00,0x00,0x00,0x00,0x00,0x00,0x00,0x00,0x00,0x00,0x00,0x00,0x00},/*"`",64*/
{0x00,0x00,0x00,0x00,0x00,0x00,0x00,0x00,0x00,0x00,0x00,0x00,0x00,0x00,0x00,0x00,0x00,0x00,0x00,0x00,0x00,0x00,0x00,0x00,0x00,0x00,0xF0,0x03,0x18,0x06,0x0C,0x0C,0x0C,0x0C,0x00,0x0C,0x80,0x0F,0x70,0x0C,0x1C,0x0C,0x0C,0x0C,0x06,0x0C,0x06,0x0C,0x06,0x4C,0x0C,0x4F,0xF8,0x38,0x00,0x00,0x00,0x00,0x00,0x00,0x00,0x00,0x00,0x00},/*"a",65*/
{0x00,0x00,0x00,0x00,0x00,0x00,0x00,0x00,0x00,0x00,0x10,0x00,0x1E,0x00,0x18,0x00,0x18,0x00,0x18,0x00,0x18,0x00,0x18,0x00,0x18,0x00,0x18,0x0F,0xD8,0x18,0x38,0x30,0x38,0x60,0x18,0x60,0x18,0x60,0x18,0x60,0x18,0x60,0x18,0x60,0x18,0x60,0x18,0x20,0x38,0x30,0x78,0x18,0xC8,0x07,0x00,0x00,0x00,0x00,0x00,0x00,0x00,0x00,0x00,0x00},/*"b",66*/
{0x00,0x00,0x00,0x00,0x00,0x00,0x00,0x00,0x00,0x00,0x00,0x00,0x00,0x00,0x00,0x00,0x00,0x00,0x00,0x00,0x00,0x00,0x00,0x00,0x00,0x00,0xC0,0x07,0x70,0x0C,0x18,0x18,0x18,0x18,0x0C,0x18,0x0C,0x00,0x0C,0x00,0x0C,0x00,0x0C,0x00,0x0C,0x20,0x18,0x20,0x18,0x10,0x30,0x08,0xC0,0x07,0x00,0x00,0x00,0x00,0x00,0x00,0x00,0x00,0x00,0x00},/*"c",67*/
{0x00,0x00,0x00,0x00,0x00,0x00,0x00,0x00,0x00,0x00,0x00,0x10,0x00,0x1E,0x00,0x18,0x00,0x18,0x00,0x18,0x00,0x18,0x00,0x18,0x00,0x18,0xE0,0x1B,0x30,0x1C,0x18,0x18,0x18,0x18,0x0C,0x18,0x0C,0x18,0x0C,0x18,0x0C,0x18,0x0C,0x18,0x0C,0x18,0x08,0x18,0x18,0x1C,0x30,0x7A,0xE0,0x09,0x00,0x00,0x00,0x00,0x00,0x00,0x00,0x00,0x00,0x00},/*"d",68*/
{0x00,0x00,0x00,0x00,0x00,0x00,0x00,0x00,0x00,0x00,0x00,0x00,0x00,0x00,0x00,0x00,0x00,0x00,0x00,0x00,0x00,0x00,0x00,0x00,0x00,0x00,0xC0,0x07,0x30,0x0C,0x18,0x18,0x08,0x10,0x0C,0x30,0x0C,0x30,0xFC,0x3F,0x0C,0x00,0x0C,0x00,0x0C,0x00,0x18,0x20,0x18,0x10,0x70,0x18,0xC0,0x07,0x00,0x00,0x00,0x00,0x00,0x00,0x00,0x00,0x00,0x00},/*"e",69*/
{0x00,0x00,0x00,0x00,0x00,0x00,0x00,0x00,0x00,0x00,0x00,0x00,0x00,0x3E,0x80,0xC3,0x80,0xC0,0xC0,0xC0,0xC0,0x00,0xC0,0x00,0xC0,0x00,0xFC,0x1F,0xC0,0x00,0xC0,0x00,0xC0,0x00,0xC0,0x00,0xC0,0x00,0xC0,0x00,0xC0,0x00,0xC0,0x00,0xC0,0x00,0xC0,0x00,0xC0,0x00,0xC0,0x00,0xF8,0x0F,0x00,0x00,0x00,0x00,0x00,0x00,0x00,0x00,0x00,0x00},/*"f",70*/
{0x00,0x00,0x00,0x00,0x00,0x00,0x00,0x00,0x00,0x00,0x00,0x00,0x00,0x00,0x00,0x00,0x00,0x00,0x00,0x00,0x00,0x00,0x00,0x00,0x00,0x00,0xC0,0x77,0x30,0x6C,0x10,0x18,0x18,0x18,0x18,0x18,0x18,0x18,0x10,0x18,0x30,0x0C,0xF0,0x07,0x18,0x00,0x18,0x00,0xF0,0x0F,0xF0,0x3F,0x08,0x70,0x0C,0x60,0x0C,0x60,0x0C,0x60,0x38,0x38,0xE0,0x0F},/*"g",71*/
{0x00,0x00,0x00,0x00,0x00,0x00,0x00,0x00,0x00,0x00,0x10,0x00,0x1E,0x00,0x18,0x00,0x18,0x00,0x18,0x00,0x18,0x00,0x18,0x00,0x18,0x00,0x98,0x0F,0xD8,0x18,0x38,0x30,0x18,0x30,0x18,0x30,0x18,0x30,0x18,0x30,0x18,0x30,0x18,0x30,0x18,0x30,0x18,0x30,0x18,0x30,0x18,0x30,0x7E,0xFC,0x00,0x00,0x00,0x00,0x00,0x00,0x00,0x00,0x00,0x00},/*"h",72*/
{0x00,0x00,0x00,0x00,0x00,0x00,0x00,0x00,0x00,0x00,0x00,0x00,0x80,0x03,0x80,0x03,0x80,0x03,0x00,0x00,0x00,0x00,0x00,0x00,0x00,0x01,0xF8,0x01,0x80,0x01,0x80,0x01,0x80,0x01,0x80,0x01,0x80,0x01,0x80,0x01,0x80,0x01,0x80,0x01,0x80,0x01,0x80,0x01,0x80,0x01,0x80,0x01,0xF8,0x1F,0x00,0x00,0x00,0x00,0x00,0x00,0x00,0x00,0x00,0x00},/*"i",73*/
{0x00,0x00,0x00,0x00,0x00,0x00,0x00,0x00,0x00,0x00,0x00,0x00,0x00,0x38,0x00,0x38,0x00,0x38,0x00,0x00,0x00,0x00,0x00,0x00,0x00,0x10,0x80,0x1F,0x00,0x18,0x00,0x18,0x00,0x18,0x00,0x18,0x00,0x18,0x00,0x18,0x00,0x18,0x00,0x18,0x00,0x18,0x00,0x18,0x00,0x18,0x00,0x18,0x00,0x18,0x00,0x18,0x00,0x18,0x18,0x0C,0x18,0x06,0xF0,0x03},/*"j",74*/
{0x00,0x00,0x00,0x00,0x00,0x00,0x00,0x00,0x00,0x00,0x10,0x00,0x1E,0x00,0x18,0x00,0x18,0x00,0x18,0x00,0x18,0x00,0x18,0x00,0x18,0x00,0x18,0x3E,0x18,0x0C,0x18,0x06,0x18,0x03,0x18,0x01,0x98,0x01,0xD8,0x01,0x38,0x03,0x18,0x07,0x18,0x06,0x18,0x0C,0x18,0x1C,0x18,0x18,0x7E,0x7C,0x00,0x00,0x00,0x00,0x00,0x00,0x00,0x00,0x00,0x00},/*"k",75*/
{0x00,0x00,0x00,0x00,0x00,0x00,0x00,0x00,0x00,0x00,0x00,0x01,0xF8,0x01,0x80,0x01,0x80,0x01,0x80,0x01,0x80,0x01,0x80,0x01,0x80,0x01,0x80,0x01,0x80,0x01,0x80,0x01,0x80,0x01,0x80,0x01,0x80,0x01,0x80,0x01,0x80,0x01,0x80,0x01,0x80,0x01,0x80,0x01,0x80,0x01,0x80,0x01,0xF8,0x1F,0x00,0x00,0x00,0x00,0x00,0x00,0x00,0x00,0x00,0x00},/*"l",76*/
{0x00,0x00,0x00,0x00,0x00,0x00,0x00,0x00,0x00,0x00,0x00,0x00,0x00,0x00,0x00,0x00,0x00,0x00,0x00,0x00,0x00,0x00,0x00,0x00,0x08,0x00,0xEE,0x1C,0x9C,0x33,0x8C,0x31,0x8C,0x31,0x8C,0x31,0x8C,0x31,0x8C,0x31,0x8C,0x31,0x8C,0x31,0x8C,0x31,0x8C,0x31,0x8C,0x31,0x8C,0x31,0xDE,0x7B,0x00,0x00,0x00,0x00,0x00,0x00,0x00,0x00,0x00,0x00},/*"m",77*/
{0x00,0x00,0x00,0x00,0x00,0x00,0x00,0x00,0x00,0x00,0x00,0x00,0x00,0x00,0x00,0x00,0x00,0x00,0x00,0x00,0x00,0x00,0x00,0x00,0x10,0x00,0x1E,0x0F,0xD8,0x18,0x38,0x30,0x18,0x30,0x18,0x30,0x18,0x30,0x18,0x30,0x18,0x30,0x18,0x30,0x18,0x30,0x18,0x30,0x18,0x30,0x18,0x30,0x7E,0xFC,0x00,0x00,0x00,0x00,0x00,0x00,0x00,0x00,0x00,0x00},/*"n",78*/
{0x00,0x00,0x00,0x00,0x00,0x00,0x00,0x00,0x00,0x00,0x00,0x00,0x00,0x00,0x00,0x00,0x00,0x00,0x00,0x00,0x00,0x00,0x00,0x00,0x00,0x00,0xC0,0x07,0x70,0x1C,0x10,0x30,0x18,0x30,0x0C,0x60,0x0C,0x60,0x0C,0x60,0x0C,0x60,0x0C,0x60,0x0C,0x60,0x18,0x30,0x18,0x30,0x30,0x18,0xC0,0x07,0x00,0x00,0x00,0x00,0x00,0x00,0x00,0x00,0x00,0x00},/*"o",79*/
{0x00,0x00,0x00,0x00,0x00,0x00,0x00,0x00,0x00,0x00,0x00,0x00,0x00,0x00,0x00,0x00,0x00,0x00,0x00,0x00,0x00,0x00,0x00,0x00,0x10,0x00,0x9E,0x0F,0x58,0x18,0x38,0x30,0x18,0x20,0x18,0x60,0x18,0x60,0x18,0x60,0x18,0x60,0x18,0x60,0x18,0x60,0x18,0x30,0x38,0x30,0x78,0x18,0x98,0x07,0x18,0x00,0x18,0x00,0x18,0x00,0x18,0x00,0x7E,0x00},/*"p",80*/
{0x00,0x00,0x00,0x00,0x00,0x00,0x00,0x00,0x00,0x00,0x00,0x00,0x00,0x00,0x00,0x00,0x00,0x00,0x00,0x00,0x00,0x00,0x00,0x00,0x00,0x00,0xC0,0x23,0x30,0x3C,0x18,0x38,0x18,0x30,0x0C,0x30,0x0C,0x30,0x0C,0x30,0x0C,0x30,0x0C,0x30,0x0C,0x30,0x08,0x30,0x18,0x38,0x30,0x3C,0xE0,0x33,0x00,0x30,0x00,0x30,0x00,0x30,0x00,0x30,0x00,0xFC},/*"q",81*/
{0x00,0x00,0x00,0x00,0x00,0x00,0x00,0x00,0x00,0x00,0x00,0x00,0x00,0x00,0x00,0x00,0x00,0x00,0x00,0x00,0x00,0x00,0x00,0x00,0x60,0x00,0x7E,0x3C,0x60,0x66,0x60,0x61,0xE0,0x00,0xE0,0x00,0x60,0x00,0x60,0x00,0x60,0x00,0x60,0x00,0x60,0x00,0x60,0x00,0x60,0x00,0x60,0x00,0xFE,0x07,0x00,0x00,0x00,0x00,0x00,0x00,0x00,0x00,0x00,0x00},/*"r",82*/
{0x00,0x00,0x00,0x00,0x00,0x00,0x00,0x00,0x00,0x00,0x00,0x00,0x00,0x00,0x00,0x00,0x00,0x00,0x00,0x00,0x00,0x00,0x00,0x00,0x00,0x00,0xE0,0x27,0x30,0x38,0x18,0x30,0x18,0x20,0x18,0x00,0x70,0x00,0xE0,0x03,0x80,0x0F,0x00,0x1C,0x04,0x30,0x04,0x30,0x0C,0x30,0x1C,0x18,0xEC,0x0F,0x00,0x00,0x00,0x00,0x00,0x00,0x00,0x00,0x00,0x00},/*"s",83*/
{0x00,0x00,0x00,0x00,0x00,0x00,0x00,0x00,0x00,0x00,0x00,0x00,0x00,0x00,0x00,0x00,0x80,0x00,0x80,0x00,0x80,0x00,0xC0,0x00,0xE0,0x00,0xFC,0x1F,0xC0,0x00,0xC0,0x00,0xC0,0x00,0xC0,0x00,0xC0,0x00,0xC0,0x00,0xC0,0x00,0xC0,0x00,0xC0,0x00,0xC0,0x20,0xC0,0x20,0x80,0x11,0x00,0x0F,0x00,0x00,0x00,0x00,0x00,0x00,0x00,0x00,0x00,0x00},/*"t",84*/
{0x00,0x00,0x00,0x00,0x00,0x00,0x00,0x00,0x00,0x00,0x00,0x00,0x00,0x00,0x00,0x00,0x00,0x00,0x00,0x00,0x00,0x00,0x00,0x00,0x10,0x20,0x1E,0x3C,0x18,0x30,0x18,0x30,0x18,0x30,0x18,0x30,0x18,0x30,0x18,0x30,0x18,0x30,0x18,0x30,0x18,0x30,0x18,0x30,0x18,0x38,0x30,0xF4,0xE0,0x13,0x00,0x00,0x00,0x00,0x00,0x00,0x00,0x00,0x00,0x00},/*"u",85*/
{0x00,0x00,0x00,0x00,0x00,0x00,0x00,0x00,0x00,0x00,0x00,0x00,0x00,0x00,0x00,0x00,0x00,0x00,0x00,0x00,0x00,0x00,0x00,0x00,0x00,0x00,0x7E,0x3C,0x18,0x18,0x18,0x08,0x38,0x08,0x30,0x04,0x30,0x04,0x70,0x02,0x60,0x02,0x60,0x02,0xE0,0x01,0xC0,0x01,0xC0,0x01,0xC0,0x00,0x80,0x00,0x00,0x00,0x00,0x00,0x00,0x00,0x00,0x00,0x00,0x00},/*"v",86*/
{0x00,0x00,0x00,0x00,0x00,0x00,0x00,0x00,0x00,0x00,0x00,0x00,0x00,0x00,0x00,0x00,0x00,0x00,0x00,0x00,0x00,0x00,0x00,0x00,0x00,0x00,0xDF,0xF7,0x8E,0x63,0x0C,0x23,0x8C,0x23,0x8C,0x23,0x98,0x13,0x98,0x13,0x58,0x16,0x58,0x16,0x70,0x0E,0x70,0x0E,0x70,0x0E,0x20,0x04,0x20,0x04,0x00,0x00,0x00,0x00,0x00,0x00,0x00,0x00,0x00,0x00},/*"w",87*/
{0x00,0x00,0x00,0x00,0x00,0x00,0x00,0x00,0x00,0x00,0x00,0x00,0x00,0x00,0x00,0x00,0x00,0x00,0x00,0x00,0x00,0x00,0x00,0x00,0x00,0x00,0xFC,0x3E,0x70,0x08,0x70,0x04,0xE0,0x04,0xC0,0x02,0xC0,0x01,0x80,0x03,0x80,0x03,0x40,0x07,0x60,0x06,0x20,0x0C,0x10,0x0C,0x18,0x18,0x3E,0x7E,0x00,0x00,0x00,0x00,0x00,0x00,0x00,0x00,0x00,0x00},/*"x",88*/
{0x00,0x00,0x00,0x00,0x00,0x00,0x00,0x00,0x00,0x00,0x00,0x00,0x00,0x00,0x00,0x00,0x00,0x00,0x00,0x00,0x00,0x00,0x00,0x00,0x00,0x00,0x7E,0x7C,0x18,0x18,0x18,0x08,0x30,0x08,0x30,0x08,0x30,0x04,0x60,0x04,0x60,0x04,0xC0,0x02,0xC0,0x02,0xC0,0x02,0x80,0x01,0x80,0x01,0x80,0x01,0x80,0x00,0x80,0x00,0x80,0x00,0x4C,0x00,0x3C,0x00},/*"y",89*/
{0x00,0x00,0x00,0x00,0x00,0x00,0x00,0x00,0x00,0x00,0x00,0x00,0x00,0x00,0x00,0x00,0x00,0x00,0x00,0x00,0x00,0x00,0x00,0x00,0x00,0x00,0xFC,0x1F,0x0C,0x0C,0x04,0x0E,0x04,0x06,0x00,0x03,0x80,0x03,0x80,0x01,0xC0,0x00,0xE0,0x00,0x70,0x20,0x30,0x20,0x38,0x30,0x1C,0x18,0xFC,0x1F,0x00,0x00,0x00,0x00,0x00,0x00,0x00,0x00,0x00,0x00},/*"z",90*/
{0x00,0x00,0x00,0x00,0x00,0x00,0x00,0x30,0x00,0x08,0x00,0x04,0x00,0x04,0x00,0x04,0x00,0x04,0x00,0x04,0x00,0x04,0x00,0x04,0x00,0x04,0x00,0x04,0x00,0x04,0x00,0x02,0x80,0x01,0x00,0x02,0x00,0x04,0x00,0x04,0x00,0x04,0x00,0x04,0x00,0x04,0x00,0x04,0x00,0x04,0x00,0x04,0x00,0x04,0x00,0x04,0x00,0x04,0x00,0x08,0x00,0x30,0x00,0x00},/*"{",91*/
{0x00,0x01,0x00,0x01,0x00,0x01,0x00,0x01,0x00,0x01,0x00,0x01,0x00,0x01,0x00,0x01,0x00,0x01,0x00,0x01,0x00,0x01,0x00,0x01,0x00,0x01,0x00,0x01,0x00,0x01,0x00,0x01,0x00,0x01,0x00,0x01,0x00,0x01,0x00,0x01,0x00,0x01,0x00,0x01,0x00,0x01,0x00,0x01,0x00,0x01,0x00,0x01,0x00,0x01,0x00,0x01,0x00,0x01,0x00,0x01,0x00,0x01,0x00,0x01},/*"|",92*/
{0x00,0x00,0x00,0x00,0x00,0x00,0x0C,0x00,0x10,0x00,0x20,0x00,0x20,0x00,0x20,0x00,0x20,0x00,0x20,0x00,0x20,0x00,0x20,0x00,0x20,0x00,0x20,0x00,0x20,0x00,0x40,0x00,0x80,0x01,0x40,0x00,0x20,0x00,0x20,0x00,0x20,0x00,0x20,0x00,0x20,0x00,0x20,0x00,0x20,0x00,0x20,0x00,0x20,0x00,0x20,0x00,0x20,0x00,0x10,0x00,0x0C,0x00,0x00,0x00},/*"}",93*/
{0x00,0x00,0x38,0x00,0xC4,0x00,0x86,0x40,0x02,0x61,0x00,0x22,0x00,0x1C,0x00,0x00,0x00,0x00,0x00,0x00,0x00,0x00,0x00,0x00,0x00,0x00,0x00,0x00,0x00,0x00,0x00,0x00,0x00,0x00,0x00,0x00,0x00,0x00,0x00,0x00,0x00,0x00,0x00,0x00,0x00,0x00,0x00,0x00,0x00,0x00,0x00,0x00,0x00,0x00,0x00,0x00,0x00,0x00,0x00,0x00,0x00,0x00,0x00,0x00},/*"~",94*/
};

/*
#define LCD_M0()     HAL_GPIO_WritePin(GPIOB, GPIO_PIN_7, 0)
#define LCD_M1()    HAL_GPIO_WritePin(GPIOB, GPIO_PIN_8, 1)
#define LCD_M2()    HAL_GPIO_WritePin(GPIOB, GPIO_PIN_9, 1)*/
/* USER CODE END PD */

RTC_HandleTypeDef hrtc;

SPI_HandleTypeDef hspi1;

TIM_HandleTypeDef htim1;

UART_HandleTypeDef huart1;

/* USER CODE BEGIN PV */

RTC_TimeTypeDef sTime;
RTC_DateTypeDef DateToUpdate;
char UTC_TIME[3];
char UTC_DATE[3];
char HOURS[20],H[20];
char MINUTES[20],MIN[20];
char SECONDS[20],S[20];
char YEAR[20],Y[20];
char MONTHS[20],MON[20];
char DATE[20],D[20];
char sensor[20];
uint8_t Rx_indx = 0;
uint8_t Rx_data = 0;
uint8_t RX_BUFFER[7];
uint8_t TX_BUFFER;
bool toggleF=true;
uint8_t mode=88;
uint8_t check=0;
bool timeupdating=0;
uint8_t timecounting=0;

/* USER CODE END PV */

void SystemClock_Config(void);
static void MX_GPIO_Init(void);
static void MX_SPI1_Init(void);
static void MX_RTC_Init(void);
static void MX_TIM1_Init(void);
static void MX_USART1_UART_Init(void);
/* USER CODE BEGIN PFP */
void LCD_Init(void);
void LCD_WriteSPI(uint8_t data);
void LCD_WriteCommand(uint8_t data);
void LCD_WriteData(uint8_t data);
void LCD_Address_Set(uint16_t x1,uint16_t y1,uint16_t x2,uint16_t y2);
void LCD_Fill(uint16_t xsta,uint16_t ysta,uint16_t xend,uint16_t yend,uint16_t color);
void LCD_DrawLine(uint16_t x1,uint16_t y1,uint16_t x2,uint16_t y2,uint16_t color);
void LCD_DrawPoint(uint16_t x,uint16_t y,uint16_t color);
void LCD_ShowChar(uint16_t x,uint16_t y,uint8_t num,uint16_t fc);
void LCD_ShowString(uint16_t x,uint16_t y,const char*p,uint16_t fc);
void display_format();
void VerticalProfileCheck();
void display_teamname();
//void askforreset();

/* USER CODE END PFP */

int main(void)
{

  /* MCU Configuration--------------------------------------------------------*/

  /* Reset of all peripherals, Initializes the Flash interface and the Systick. */
  HAL_Init();

  /* Configure the system clock */
  SystemClock_Config();

  /* Initialize all configured peripherals */
  MX_GPIO_Init();
  MX_SPI1_Init();
  MX_RTC_Init();
  MX_TIM1_Init();
  MX_USART1_UART_Init();
  /* USER CODE BEGIN 2 */
	LCD_Init();
	LCD_Fill(0,0,320,240,0x0000);
	display_format();
	VerticalProfileCheck();
	HAL_UART_Receive_IT(&huart1, &Rx_data, 1);

	//HAL_UART_Receive_IT(&huart1, &Rx_data, 1);
	//VerticalProfileCheck();

  /* USER CODE END 2 */

  /* Infinite loop */
  while (1)
  {

    /* USER CODE BEGIN 3 */
		//HAL_UART_Receive_IT(&huart1, &Rx_data, 1);

		if(mode==88&&!HAL_GPIO_ReadPin(GPIOA, GPIO_PIN_8)){
			mode=77;
			VerticalProfileCheck();
			TX_BUFFER=77;
			HAL_UART_Transmit(&huart1, &TX_BUFFER, 1, 100);
		}
		if(mode==77&&!HAL_GPIO_ReadPin(GPIOA, GPIO_PIN_8)){
			mode=66;
			VerticalProfileCheck();
			TX_BUFFER=66;
			HAL_UART_Transmit(&huart1, &TX_BUFFER, 1, 100);
		}
		if(mode==66&&!HAL_GPIO_ReadPin(GPIOA, GPIO_PIN_8)){
			mode=80;
			TX_BUFFER=80;
			HAL_UART_Transmit(&huart1, &TX_BUFFER, 1, 100);
			VerticalProfileCheck();
		}
		if(mode==80&&!HAL_GPIO_ReadPin(GPIOA, GPIO_PIN_8)){
			mode=88;
			TX_BUFFER=88;
			HAL_UART_Transmit(&huart1, &TX_BUFFER, 1, 100);
			VerticalProfileCheck();
		}

//		if(!HAL_GPIO_ReadPin(GPIOA, GPIO_PIN_7)){
//				mode=88;
//				TX_BUFFER=88;
//				HAL_UART_Transmit(&huart1, &TX_BUFFER, 1, 100);
//				VerticalProfileCheck();
//
//		}

		sprintf((char*)H,"%02d",RX_BUFFER[0]); //strncpy(HOURS, H, 20);
		sprintf((char*)MIN,"%02d",RX_BUFFER[1]); //strncpy(MINUTES, MIN, 20);
		sprintf((char*)S,"%02d",RX_BUFFER[2]); //strncpy(SECONDS, S, 20);
		sprintf((char*)Y,"%02d",RX_BUFFER[3]+2000); //strncpy(YEAR, Y, 20);
		sprintf((char*)MON,"%02d",RX_BUFFER[4]); //st rncpy(MONTHS, MON, 20);
		sprintf((char*)D,"%02d",RX_BUFFER[5]); //strncpy(DATE, D, 20);

		//sprintf((char*)sensor,"%02d",RX_BUFFER[7]); //strncpy(DATE, D, 20);

		if(strcmp(HOURS, H) != 0 ){
			LCD_ShowString(96,136,HOURS,0x0000);//HOURS
			strncpy(HOURS, H, 20);
			LCD_ShowString(96,136,HOURS,0xFFFF);//HOURS

		}
		if(strcmp(MINUTES, MIN) != 0 ){
			LCD_ShowString(144,136,MINUTES,0x0000);//MINUTES
			strncpy(MINUTES, MIN, 20);
			LCD_ShowString(144,136,MINUTES,0xFFFF);//MINUTES

		}
		if(strcmp(SECONDS, S) != 0 ){
			LCD_ShowString(192,136,SECONDS,0x0000);//SECONDS
			strncpy(SECONDS, S, 20);
			LCD_ShowString(192,136,SECONDS,0xFFFF);//SECONDS
			//display_teamname();

			if(mode==77){
				timecounting++;
				if(timecounting==15)
				display_teamname();
			}

		}

		if(strcmp(YEAR, Y) != 0 ){
			LCD_ShowString(80,170,YEAR,0x0000);//YEAR
			strncpy(YEAR, Y, 20);
			LCD_ShowString(80,170,YEAR,0xFFFF);//YEAR

		}
		if(strcmp(MONTHS, MON) != 0 ){
			LCD_ShowString(160,170,MONTHS,0x0000);//MONTHS
			strncpy(MONTHS, MON, 20);
			LCD_ShowString(160,170,MONTHS,0xFFFF);//MONTHS

		}if(strcmp(DATE, D) != 0 ){
			LCD_ShowString(208,170,DATE,0x0000);//DATE
			strncpy(DATE, D, 20);
			LCD_ShowString(208,170,DATE,0xFFFF);//DATE

		}
		HAL_Delay(100);

  }
  /* USER CODE END 3 */
}

void SystemClock_Config(void)
{
  RCC_OscInitTypeDef RCC_OscInitStruct = {0};
  RCC_ClkInitTypeDef RCC_ClkInitStruct = {0};
  RCC_PeriphCLKInitTypeDef PeriphClkInit = {0};

  /** Initializes the RCC Oscillators according to the specified parameters
  * in the RCC_OscInitTypeDef structure.
  */
  RCC_OscInitStruct.OscillatorType = RCC_OSCILLATORTYPE_HSE;
  RCC_OscInitStruct.HSEState = RCC_HSE_ON;
  RCC_OscInitStruct.HSEPredivValue = RCC_HSE_PREDIV_DIV1;
  RCC_OscInitStruct.HSIState = RCC_HSI_ON;
  RCC_OscInitStruct.PLL.PLLState = RCC_PLL_ON;
  RCC_OscInitStruct.PLL.PLLSource = RCC_PLLSOURCE_HSE;
  RCC_OscInitStruct.PLL.PLLMUL = RCC_PLL_MUL9;
  if (HAL_RCC_OscConfig(&RCC_OscInitStruct) != HAL_OK)
  {
    Error_Handler();
  }

  /** Initializes the CPU, AHB and APB buses clocks
  */
  RCC_ClkInitStruct.ClockType = RCC_CLOCKTYPE_HCLK|RCC_CLOCKTYPE_SYSCLK
                              |RCC_CLOCKTYPE_PCLK1|RCC_CLOCKTYPE_PCLK2;
  RCC_ClkInitStruct.SYSCLKSource = RCC_SYSCLKSOURCE_PLLCLK;
  RCC_ClkInitStruct.AHBCLKDivider = RCC_SYSCLK_DIV1;
  RCC_ClkInitStruct.APB1CLKDivider = RCC_HCLK_DIV2;
  RCC_ClkInitStruct.APB2CLKDivider = RCC_HCLK_DIV1;

  if (HAL_RCC_ClockConfig(&RCC_ClkInitStruct, FLASH_LATENCY_2) != HAL_OK)
  {
    Error_Handler();
  }
  PeriphClkInit.PeriphClockSelection = RCC_PERIPHCLK_RTC;
  PeriphClkInit.RTCClockSelection = RCC_RTCCLKSOURCE_HSE_DIV128;
  if (HAL_RCCEx_PeriphCLKConfig(&PeriphClkInit) != HAL_OK)
  {
    Error_Handler();
  }
}

static void MX_RTC_Init(void)
{

  RTC_TimeTypeDef sTime = {0};
  RTC_DateTypeDef DateToUpdate = {0};

  /** Initialize RTC Only
  */
  hrtc.Instance = RTC;
  hrtc.Init.AsynchPrediv = RTC_AUTO_1_SECOND;
  hrtc.Init.OutPut = RTC_OUTPUTSOURCE_ALARM;
  if (HAL_RTC_Init(&hrtc) != HAL_OK)
  {
    Error_Handler();
  }

  /** Initialize RTC and set the Time and Date
  */
  sTime.Hours = 11;
  sTime.Minutes = 47;
  sTime.Seconds = 0;

  if (HAL_RTC_SetTime(&hrtc, &sTime, RTC_FORMAT_BIN) != HAL_OK)
  {
    Error_Handler();
  }
  DateToUpdate.WeekDay = RTC_WEEKDAY_SUNDAY;
  DateToUpdate.Month = RTC_MONTH_JANUARY;
  DateToUpdate.Date = 15;
  DateToUpdate.Year = 23;

  if (HAL_RTC_SetDate(&hrtc, &DateToUpdate, RTC_FORMAT_BIN) != HAL_OK)
  {
    Error_Handler();
  }

}

static void MX_SPI1_Init(void)
{

  /* SPI1 parameter configuration*/
  hspi1.Instance = SPI1;
  hspi1.Init.Mode = SPI_MODE_MASTER;
  hspi1.Init.Direction = SPI_DIRECTION_2LINES;
  hspi1.Init.DataSize = SPI_DATASIZE_8BIT;
  hspi1.Init.CLKPolarity = SPI_POLARITY_LOW;
  hspi1.Init.CLKPhase = SPI_PHASE_1EDGE;
  hspi1.Init.NSS = SPI_NSS_SOFT;
  hspi1.Init.BaudRatePrescaler = SPI_BAUDRATEPRESCALER_4;
  hspi1.Init.FirstBit = SPI_FIRSTBIT_MSB;
  hspi1.Init.TIMode = SPI_TIMODE_DISABLE;
  hspi1.Init.CRCCalculation = SPI_CRCCALCULATION_DISABLE;
  hspi1.Init.CRCPolynomial = 10;
  if (HAL_SPI_Init(&hspi1) != HAL_OK)
  {
    Error_Handler();
  }

}

static void MX_TIM1_Init(void)
{

  TIM_ClockConfigTypeDef sClockSourceConfig = {0};
  TIM_SlaveConfigTypeDef sSlaveConfig = {0};
  TIM_MasterConfigTypeDef sMasterConfig = {0};
  TIM_OC_InitTypeDef sConfigOC = {0};
  TIM_BreakDeadTimeConfigTypeDef sBreakDeadTimeConfig = {0};

  htim1.Instance = TIM1;
  htim1.Init.Prescaler = 0;
  htim1.Init.CounterMode = TIM_COUNTERMODE_UP;
  htim1.Init.Period = 65535;
  htim1.Init.ClockDivision = TIM_CLOCKDIVISION_DIV1;
  htim1.Init.RepetitionCounter = 0;
  htim1.Init.AutoReloadPreload = TIM_AUTORELOAD_PRELOAD_DISABLE;
  if (HAL_TIM_Base_Init(&htim1) != HAL_OK)
  {
    Error_Handler();
  }
  sClockSourceConfig.ClockSource = TIM_CLOCKSOURCE_INTERNAL;
  if (HAL_TIM_ConfigClockSource(&htim1, &sClockSourceConfig) != HAL_OK)
  {
    Error_Handler();
  }
  if (HAL_TIM_OC_Init(&htim1) != HAL_OK)
  {
    Error_Handler();
  }
  sSlaveConfig.SlaveMode = TIM_SLAVEMODE_DISABLE;
  sSlaveConfig.InputTrigger = TIM_TS_ITR1;
  if (HAL_TIM_SlaveConfigSynchro(&htim1, &sSlaveConfig) != HAL_OK)
  {
    Error_Handler();
  }
  sMasterConfig.MasterOutputTrigger = TIM_TRGO_RESET;
  sMasterConfig.MasterSlaveMode = TIM_MASTERSLAVEMODE_DISABLE;
  if (HAL_TIMEx_MasterConfigSynchronization(&htim1, &sMasterConfig) != HAL_OK)
  {
    Error_Handler();
  }
  sConfigOC.OCMode = TIM_OCMODE_TIMING;
  sConfigOC.Pulse = 0;
  sConfigOC.OCPolarity = TIM_OCPOLARITY_HIGH;
  sConfigOC.OCNPolarity = TIM_OCNPOLARITY_HIGH;
  sConfigOC.OCFastMode = TIM_OCFAST_DISABLE;
  sConfigOC.OCIdleState = TIM_OCIDLESTATE_RESET;
  sConfigOC.OCNIdleState = TIM_OCNIDLESTATE_RESET;
  if (HAL_TIM_OC_ConfigChannel(&htim1, &sConfigOC, TIM_CHANNEL_1) != HAL_OK)
  {
    Error_Handler();
  }
  sBreakDeadTimeConfig.OffStateRunMode = TIM_OSSR_DISABLE;
  sBreakDeadTimeConfig.OffStateIDLEMode = TIM_OSSI_DISABLE;
  sBreakDeadTimeConfig.LockLevel = TIM_LOCKLEVEL_OFF;
  sBreakDeadTimeConfig.DeadTime = 0;
  sBreakDeadTimeConfig.BreakState = TIM_BREAK_DISABLE;
  sBreakDeadTimeConfig.BreakPolarity = TIM_BREAKPOLARITY_HIGH;
  sBreakDeadTimeConfig.AutomaticOutput = TIM_AUTOMATICOUTPUT_DISABLE;
  if (HAL_TIMEx_ConfigBreakDeadTime(&htim1, &sBreakDeadTimeConfig) != HAL_OK)
  {
    Error_Handler();
  }

}

static void MX_USART1_UART_Init(void)
{

  huart1.Instance = USART1;
  huart1.Init.BaudRate = 9600;
  huart1.Init.WordLength = UART_WORDLENGTH_8B;
  huart1.Init.StopBits = UART_STOPBITS_1;
  huart1.Init.Parity = UART_PARITY_NONE;
  huart1.Init.Mode = UART_MODE_TX_RX;
  huart1.Init.HwFlowCtl = UART_HWCONTROL_NONE;
  huart1.Init.OverSampling = UART_OVERSAMPLING_16;
  if (HAL_UART_Init(&huart1) != HAL_OK)
  {
    Error_Handler();
  }

}

static void MX_GPIO_Init(void)
{
  GPIO_InitTypeDef GPIO_InitStruct = {0};

  /* GPIO Ports Clock Enable */
  __HAL_RCC_GPIOD_CLK_ENABLE();
  __HAL_RCC_GPIOA_CLK_ENABLE();
  __HAL_RCC_GPIOB_CLK_ENABLE();

  /*Configure GPIO pin Output Level */
  HAL_GPIO_WritePin(GPIOB, GPIO_PIN_0|GPIO_PIN_1|GPIO_PIN_2|GPIO_PIN_10
                          |GPIO_PIN_15, GPIO_PIN_RESET);

  /*Configure GPIO pins : PA7 PA8 */
  GPIO_InitStruct.Pin = GPIO_PIN_7|GPIO_PIN_8;
  GPIO_InitStruct.Mode = GPIO_MODE_INPUT;
  GPIO_InitStruct.Pull = GPIO_PULLUP;
  HAL_GPIO_Init(GPIOA, &GPIO_InitStruct);

  /*Configure GPIO pins : PB0 PB1 PB2 PB10
                           PB15 */
  GPIO_InitStruct.Pin = GPIO_PIN_0|GPIO_PIN_1|GPIO_PIN_2|GPIO_PIN_10
                          |GPIO_PIN_15;
  GPIO_InitStruct.Mode = GPIO_MODE_OUTPUT_PP;
  GPIO_InitStruct.Pull = GPIO_NOPULL;
  GPIO_InitStruct.Speed = GPIO_SPEED_FREQ_LOW;
  HAL_GPIO_Init(GPIOB, &GPIO_InitStruct);

}

/* USER CODE BEGIN 4 */
void HAL_UART_RxCpltCallback(UART_HandleTypeDef *huart)
{
		//For UTC time

		if (huart->Instance==USART1) { // Current UART
			RX_BUFFER[Rx_indx++] = Rx_data;    // Add data to Rx_Buffer
   }
	 if(Rx_indx!=7&&Rx_data==0xff){Rx_indx=0;}
	 if(Rx_indx==7){Rx_indx=0;}
	 HAL_UART_Receive_IT(&huart1, &Rx_data, 1);

}

void LCD_Init(void){

	LCD_CS_HIGH();
	HAL_Delay(10);
	LCD_CS_LOW();//the serial interface is initialized when CSX is high. P56
								// SCL and SDA no effect

	LCD_REST_LOW();
	//HAL_Delay(1000);
	LCD_REST_HIGH();
	//HAL_Delay(10000);

	LCD_CS_HIGH();
	LCD_WriteCommand(0x01); //software reset
	//LCD_WriteCommand(0x28); //DISPLAY OFF
	LCD_WriteCommand(0x11); //sleep out
	HAL_Delay(10);

	//LCD_M0();
	//LCD_M1();
	//LCD_M2();

	LCD_WriteCommand(0x36); //Memory Data Access Control
	LCD_WriteData(0x40);

	LCD_WriteCommand(0x3A);//Interface Pixel Format
	LCD_WriteData(0x05); //?101? = 16bit/pixel

	LCD_WriteCommand(0xB2);//Porch Setting
	LCD_WriteData(0x0C);
	LCD_WriteData(0x0C);
	LCD_WriteData(0x00);
	LCD_WriteData(0x33);
	LCD_WriteData(0x33);

	LCD_WriteCommand(0xB7); //Gate Control
	LCD_WriteData(0x35);

	LCD_WriteCommand(0xBB);//VCOM Setting
	LCD_WriteData(0x35);

	LCD_WriteCommand(0xC0);//LCM Control .
	LCD_WriteData(0x2C);

	LCD_WriteCommand(0xC2);//VDV and VRH Command Enable
	LCD_WriteData(0x01);
	LCD_WriteData(0xFF);

	LCD_WriteCommand(0xC3);//VRH Set
	LCD_WriteData(0x13);

	LCD_WriteCommand(0xC4);//VDV Set
	LCD_WriteData(0x20);

	LCD_WriteCommand(0xC6); // Frame Rate Control in Normal Mode
	LCD_WriteData(0x0F);

	LCD_WriteCommand(0xD0); //Power Control 1
	LCD_WriteData(0xA4);
	LCD_WriteData(0xA1);

	LCD_WriteCommand(0xE0);
  LCD_WriteData(0xF0);
  LCD_WriteData(0x00);
  LCD_WriteData(0x04);
  LCD_WriteData(0x04);
  LCD_WriteData(0x04);
  LCD_WriteData(0x05);
  LCD_WriteData(0x29);
  LCD_WriteData(0x33);
  LCD_WriteData(0x3E);
  LCD_WriteData(0x38);
  LCD_WriteData(0x12);
  LCD_WriteData(0x12);
  LCD_WriteData(0x28);
  LCD_WriteData(0x30);

	LCD_WriteCommand(0xE1);
	LCD_WriteData(0xF0);
  LCD_WriteData(0x07);
  LCD_WriteData(0x0A);
  LCD_WriteData(0x0D);
  LCD_WriteData(0x0B);
  LCD_WriteData(0x07);
  LCD_WriteData(0x28);
  LCD_WriteData(0x33);
  LCD_WriteData(0x3E);
  LCD_WriteData(0x36);
  LCD_WriteData(0x14);
  LCD_WriteData(0x14);
  LCD_WriteData(0x29);
  LCD_WriteData(0x32);

	//LCD_WriteCommand(0x21); //Display Inversion On

  LCD_WriteCommand(0x11); //Sleep out
	LCD_WriteCommand(0x13); //Nomal diaplay on
	LCD_WriteCommand(0x38); //idle off
	LCD_WriteCommand(0x29);//:Display On

	//LCD_WriteCommand(0x51);//Write Display Brightness
	//LCD_WriteData(0x00);

}

void LCD_WriteSPI(uint8_t data){
	HAL_SPI_Transmit(&hspi1, &data, 1, 0xffff);
}

void LCD_WriteCommand(uint8_t data){
	LCD_CS_LOW();
	LCD_DC_LOW();
	LCD_WriteSPI(data);
	LCD_DC_HIGH();
	LCD_CS_HIGH();
}

void LCD_WriteData(uint8_t data){
	LCD_CS_LOW();
	LCD_DC_HIGH();
	LCD_WriteSPI(data);
	LCD_DC_LOW();
	LCD_CS_HIGH();
}

void LCD_Address_Set(uint16_t x1,uint16_t y1,uint16_t x2,uint16_t y2){

	LCD_WriteCommand(0x2b);	//row

	LCD_WriteData(x1>>8);
	LCD_WriteData(x1);
	LCD_WriteData(x2>>8);
	LCD_WriteData(x2);

	LCD_WriteCommand(0x2a);	//col
	LCD_WriteData(y1>>8);
	LCD_WriteData(y1);
	LCD_WriteData(y2>>8);
	LCD_WriteData(y2);

	LCD_WriteCommand(0x2c);	//Memory write
}
void LCD_Fill(uint16_t xsta,uint16_t ysta,uint16_t xend,uint16_t yend,uint16_t color)
{
	uint16_t i,j;
	LCD_Address_Set(xsta,ysta,xend-1,yend-1);
	for(i=xsta;i<xend;i++)
	{
		for(j=ysta;j<yend;j++)
		{
			LCD_WriteData(color);
			LCD_WriteData(color>>8);
		}
	}
}

void LCD_DrawPoint(uint16_t x,uint16_t y,uint16_t color)
{
	LCD_Address_Set(x,y,x,y);
	LCD_WriteData(color);
	LCD_WriteData(color>>8);
}

void LCD_DrawLine(uint16_t x1,uint16_t y1,uint16_t x2,uint16_t y2,uint16_t color)
{

	uint16_t i,j;
	LCD_Address_Set(x1,y1,x2-1,y2-1);
	for(i=x1;i<x2;i++)
	{
		for(j=y1;j<y2;j++)
		{
			LCD_WriteData(color);
			LCD_WriteData(color>>8);
		}
	}

}

void LCD_ShowChar(uint16_t x,uint16_t y,uint8_t num,uint16_t fc)
{
	uint8_t temp,sizex,t,sizey=32;
	uint16_t i,TypefaceNum;
	uint16_t x0=x;
	sizex=sizey/2;
	TypefaceNum=(sizex/8+((sizex%8)?1:0))*sizey;
	num=num-' ';
	LCD_Address_Set(x,y,x+sizex-1,y+sizey-1);

for(i=0;i<TypefaceNum;i++)
	{
		for(t=0;t<8;t++)
		{
				temp=ascii_3216[num][i];
				if(temp&(0x01<<t))
					LCD_DrawPoint(x,y,fc);
				x++;
				if((x-x0)==sizex)
				{
					x=x0;
					y++;
					break;
				}
			}
		}
}

void LCD_ShowString(uint16_t x,uint16_t y,const char *p,uint16_t fc)
{

	while(*p!='\0')
	{
		LCD_ShowChar(x,y,*p,fc);
		x+=32/2;
		p++;
	}
}

/*
display: X x Y= 320x240
font size: x,y=32,16

pure letters(L) or numbers(N): total 20 Ls/Ns
each line -> 34: 7 Rows

LCD_ShowString(0,0,"ABCDEFGHIJKLMNOPWRST",0x07E0);
LCD_ShowString(0,34,"0123456789abcdefghij",0x07E0);
*/
void display_format(){

	//FOR DISPLAY TIME
	LCD_ShowString(128,136,":",0xFFFF);
	LCD_ShowString(176,136,":",0xFFFF);
	//FOR DISPLAY DATE
	LCD_ShowString(144,170,"-",0xFFFF);
	LCD_ShowString(192,170,"-",0xFFFF);

	//DISPLAY TEAM NAME
	LCD_ShowString(80,68,"Team Name1",0xffff); //line3

}

void display_teamname(){
	//DISPLAY TEAM NAME
	LCD_Fill(0,68,320,102,0x0000);
	LCD_ShowString(128,68,"EX07",0xffff); //line3

}

void VerticalProfileCheck(){
		if(mode==99){
			LCD_Fill(0,0,320,68,0x0000);
			LCD_ShowString(0,0,"Device Disconnected",0xffff); //line3
		}
		if(mode==88){
			LCD_Fill(0,0,320,68,0x0000);
			LCD_ShowString(32,0,"Device is ready!",0xffff); //line3
		}

		if(mode==80){
			LCD_Fill(0,0,320,68,0x0000);
			LCD_ShowString(32,0,"Task Finished!!!",0xffff); //line3
		}
	if(mode==77){
			LCD_Fill(0,0,320,68,0x0000);
			LCD_ShowString(0,0,"1st Vertical Profile",0xffff); //line3
			//send and indicaet to run first profile

		}
	if(mode==66){
		LCD_Fill(0,0,320,68,0x0000);
		LCD_ShowString(0,0,"2nd Vertical Profile",0xffff); //line3

		//send and indicaet to run second profile
		}

}

//void askforreset(){

//	while(mode==99){
//		//LCD_Fill(0,0,320,68,0x2112);
//		LCD_ShowString(0,0,"Device Disconnected",0xffff); //line3
//		while(1){
//			TX_BUFFER=88;
//			HAL_UART_Transmit(&huart1, &TX_BUFFER, 1, 100);
//			if(Rx_data==88){
//				mode=88;
//				break;
//			}
//		}
//	}
//	VerticalProfileCheck();

//}

/* USER CODE END 4 */

void Error_Handler(void)
{
}
